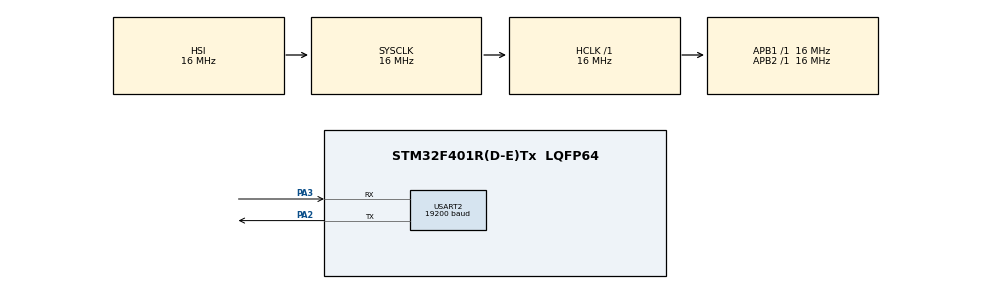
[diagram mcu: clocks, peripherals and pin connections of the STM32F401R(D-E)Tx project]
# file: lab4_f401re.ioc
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Mcu.Family=STM32F4
Dma.USART2_TX.1.Priority=DMA_PRIORITY_LOW
RCC.CortexFreq_Value=16000000
Dma.USART2_TX.1.FIFOMode=DMA_FIFOMODE_DISABLE
Dma.USART2_TX.1.MemInc=DMA_MINC_ENABLE
Dma.USART2_RX.0.Direction=DMA_PERIPH_TO_MEMORY
Dma.USART2_TX.1.PeriphDataAlignment=DMA_PDATAALIGN_BYTE
NVIC.USART2_IRQn=true\:0\:0\:false\:false\:true\:true\:true
USART2.BaudRate=19200
ProjectManager.StackSize=0x400
Dma.USART2_RX.0.Mode=DMA_CIRCULAR
PA3.Mode=Asynchronous
TIM1.Prescaler=15999
ProjectManager.TargetToolchain=STM32CubeIDE
NVIC.DMA1_Stream5_IRQn=true\:0\:0\:false\:false\:true\:false\:true
Dma.USART2_RX.0.Priority=DMA_PRIORITY_LOW
Dma.USART2_RX.0.PeriphDataAlignment=DMA_PDATAALIGN_BYTE
Dma.USART2_TX.1.Mode=DMA_NORMAL
RCC.LSE_VALUE=32768
RCC.AHBFreq_Value=16000000
RCC.HSE_VALUE=25000000
Dma.USART2_TX.1.PeriphInc=DMA_PINC_DISABLE
board=custom
RCC.VCOOutputFreq_Value=192000000
Dma.USART2_TX.1.Direction=DMA_MEMORY_TO_PERIPH
RCC.APB2Freq_Value=16000000
Dma.USART2_RX.0.MemDataAlignment=DMA_MDATAALIGN_BYTE
Dma.USART2_TX.1.Instance=DMA1_Stream6
Dma.USART2_RX.0.Instance=DMA1_Stream5
Mcu.Name=STM32F401R(D-E)Tx
Dma.USART2_RX.0.MemInc=DMA_MINC_ENABLE
VP_TIM1_VS_ClockSourceINT.Mode=Internal
PA2.Signal=USART2_TX
RCC.SYSCLKFreq_VALUE=16000000
Mcu.Package=LQFP64
Dma.USART2_RX.0.PeriphInc=DMA_PINC_DISABLE
USART2.VirtualMode=VM_ASYNC
Dma.USART2_RX.0.FIFOMode=DMA_FIFOMODE_DISABLE
ProjectManager.HeapSize=0x200
NVIC.TIM1_UP_TIM10_IRQn=true\:0\:0\:false\:false\:true\:true\:true
RCC.HSI_VALUE=16000000
NVIC.PriorityGroup=NVIC_PRIORITYGROUP_4
Dma.Request1=USART2_TX
PA2.Mode=Asynchronous
TIM1.Period=9
Dma.USART2_TX.1.MemDataAlignment=DMA_MDATAALIGN_BYTE
RCC.APB1Freq_Value=16000000
NVIC.DMA1_Stream6_IRQn=true\:0\:0\:false\:false\:true\:false\:true
Dma.Request0=USART2_RX
PA3.Signal=USART2_RX

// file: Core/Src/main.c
/* USER CODE BEGIN Header */
/**
  ******************************************************************************
  * @file           : main.c
  * @brief          : Main program body
  ******************************************************************************
  * @attention
  *
  * <h2><center>&copy; Copyright (c) 2023 STMicroelectronics.
  * All rights reserved.</center></h2>
  *
  * This software component is licensed by ST under BSD 3-Clause license,
  * the "License"; You may not use this file except in compliance with the
  * License. You may obtain a copy of the License at:
  *                        opensource.org/licenses/BSD-3-Clause
  *
  ******************************************************************************
  */
/* USER CODE END Header */
#include "main.h"

/* USER CODE BEGIN Includes */
#include <math.h>
/* USER CODE END Includes */

TIM_HandleTypeDef htim1;

UART_HandleTypeDef huart2;
DMA_HandleTypeDef hdma_usart2_rx;
DMA_HandleTypeDef hdma_usart2_tx;

/* USER CODE BEGIN PV */
float t;  // time

float bias = 1;
float amp = 1;
float freq = 1;
float phase = 1;

//typedef struct {
//	uint8_t header;
//	float bias;
//	float amp;
//	float freq;
//	float phase;
//	uint8_t terminator;
//} rx_struct;
//rx_struct rx_buffer;

typedef struct {
	uint8_t header[4];
	float t;
	float val;
	uint8_t terminator[4];
} tx_struct;

tx_struct tx_buffer = {"NNNN", 0.0, 0.0, "EEEE"};

//uint8_t have_params = 0;  // flag of having params of calculation
/* USER CODE END PV */

void SystemClock_Config(void);
static void MX_GPIO_Init(void);
static void MX_DMA_Init(void);
static void MX_USART2_UART_Init(void);
static void MX_TIM1_Init(void);

int main(void)
{

  /* MCU Configuration--------------------------------------------------------*/

  /* Reset of all peripherals, Initializes the Flash interface and the Systick. */
  HAL_Init();

  /* Configure the system clock */
  SystemClock_Config();

  /* Initialize all configured peripherals */
  MX_GPIO_Init();
  MX_DMA_Init();
  MX_USART2_UART_Init();
  MX_TIM1_Init();
  /* USER CODE BEGIN 2 */
  t = 0.0;

  HAL_TIM_Base_Start_IT(&htim1);
  //HAL_UART_Receive_DMA(&huart2, (uint8_t*)&rx_buffer, sizeof(rx_buffer));

  //while (!have_params);
  /* USER CODE END 2 */

  /* Infinite loop */
  /* USER CODE BEGIN WHILE */
  while (1)
  {
	//bias = rx_buffer.bias;
	//amp = rx_buffer.amp;
	//freq = rx_buffer.freq;
	//phase = rx_buffer.phase;

	tx_buffer.t = t;
	tx_buffer.val = bias + amp*sinf(freq*t + phase);
    /* USER CODE END WHILE */

  }
}

void SystemClock_Config(void)
{
  RCC_OscInitTypeDef RCC_OscInitStruct = {0};
  RCC_ClkInitTypeDef RCC_ClkInitStruct = {0};

  /** Configure the main internal regulator output voltage
  */
  __HAL_RCC_PWR_CLK_ENABLE();
  __HAL_PWR_VOLTAGESCALING_CONFIG(PWR_REGULATOR_VOLTAGE_SCALE2);
  /** Initializes the RCC Oscillators according to the specified parameters
  * in the RCC_OscInitTypeDef structure.
  */
  RCC_OscInitStruct.OscillatorType = RCC_OSCILLATORTYPE_HSI;
  RCC_OscInitStruct.HSIState = RCC_HSI_ON;
  RCC_OscInitStruct.HSICalibrationValue = RCC_HSICALIBRATION_DEFAULT;
  RCC_OscInitStruct.PLL.PLLState = RCC_PLL_NONE;
  if (HAL_RCC_OscConfig(&RCC_OscInitStruct) != HAL_OK)
  {
    Error_Handler();
  }
  /** Initializes the CPU, AHB and APB buses clocks
  */
  RCC_ClkInitStruct.ClockType = RCC_CLOCKTYPE_HCLK|RCC_CLOCKTYPE_SYSCLK
                              |RCC_CLOCKTYPE_PCLK1|RCC_CLOCKTYPE_PCLK2;
  RCC_ClkInitStruct.SYSCLKSource = RCC_SYSCLKSOURCE_HSI;
  RCC_ClkInitStruct.AHBCLKDivider = RCC_SYSCLK_DIV1;
  RCC_ClkInitStruct.APB1CLKDivider = RCC_HCLK_DIV1;
  RCC_ClkInitStruct.APB2CLKDivider = RCC_HCLK_DIV1;

  if (HAL_RCC_ClockConfig(&RCC_ClkInitStruct, FLASH_LATENCY_0) != HAL_OK)
  {
    Error_Handler();
  }
}

static void MX_TIM1_Init(void)
{

  TIM_ClockConfigTypeDef sClockSourceConfig = {0};
  TIM_MasterConfigTypeDef sMasterConfig = {0};

  htim1.Instance = TIM1;
  htim1.Init.Prescaler = 15999;
  htim1.Init.CounterMode = TIM_COUNTERMODE_UP;
  htim1.Init.Period = 9;
  htim1.Init.ClockDivision = TIM_CLOCKDIVISION_DIV1;
  htim1.Init.RepetitionCounter = 0;
  htim1.Init.AutoReloadPreload = TIM_AUTORELOAD_PRELOAD_DISABLE;
  if (HAL_TIM_Base_Init(&htim1) != HAL_OK)
  {
    Error_Handler();
  }
  sClockSourceConfig.ClockSource = TIM_CLOCKSOURCE_INTERNAL;
  if (HAL_TIM_ConfigClockSource(&htim1, &sClockSourceConfig) != HAL_OK)
  {
    Error_Handler();
  }
  sMasterConfig.MasterOutputTrigger = TIM_TRGO_RESET;
  sMasterConfig.MasterSlaveMode = TIM_MASTERSLAVEMODE_DISABLE;
  if (HAL_TIMEx_MasterConfigSynchronization(&htim1, &sMasterConfig) != HAL_OK)
  {
    Error_Handler();
  }

}

static void MX_USART2_UART_Init(void)
{

  huart2.Instance = USART2;
  huart2.Init.BaudRate = 19200;
  huart2.Init.WordLength = UART_WORDLENGTH_8B;
  huart2.Init.StopBits = UART_STOPBITS_1;
  huart2.Init.Parity = UART_PARITY_NONE;
  huart2.Init.Mode = UART_MODE_TX_RX;
  huart2.Init.HwFlowCtl = UART_HWCONTROL_NONE;
  huart2.Init.OverSampling = UART_OVERSAMPLING_16;
  if (HAL_UART_Init(&huart2) != HAL_OK)
  {
    Error_Handler();
  }

}

static void MX_DMA_Init(void)
{

  /* DMA controller clock enable */
  __HAL_RCC_DMA1_CLK_ENABLE();

  /* DMA interrupt init */
  /* DMA1_Stream5_IRQn interrupt configuration */
  HAL_NVIC_SetPriority(DMA1_Stream5_IRQn, 0, 0);
  HAL_NVIC_EnableIRQ(DMA1_Stream5_IRQn);
  /* DMA1_Stream6_IRQn interrupt configuration */
  HAL_NVIC_SetPriority(DMA1_Stream6_IRQn, 0, 0);
  HAL_NVIC_EnableIRQ(DMA1_Stream6_IRQn);

}

static void MX_GPIO_Init(void)
{

  /* GPIO Ports Clock Enable */
  __HAL_RCC_GPIOA_CLK_ENABLE();

}

/* USER CODE BEGIN 4 */
//void HAL_UART_RxCpltCallback(UART_HandleTypeDef* huart)
//{
//	have_params = 1;
//}

void HAL_TIM_PeriodElapsedCallback(TIM_HandleTypeDef* htim)
{
	t += 0.01;
	//if (have_params) {
	HAL_UART_Transmit_DMA(&huart2, (uint8_t*)&tx_buffer, sizeof(tx_buffer));
	//}
}
/* USER CODE END 4 */

void Error_Handler(void)
{
  __disable_irq();
  while (1)
  {
  }
}

/************************ (C) COPYRIGHT STMicroelectronics *****END OF FILE****/
